# DEBUGSS_DRM register map
Vendor: Texas Instruments
Peripheral module from a debugger description file (folder am437x).
Registers are 32-bit, access per field, no defined reset value unless marked. A register's access mark holds for its fields unless they carry their own. Offsets are as the file gives them; lines under a group give offsets from that group; [hi:lo] are bit positions; {n}, {i} and the like mark numbered series; 'fields as' and 'values as' point back to an identical list; <NAME> marks a mode.

## DRM
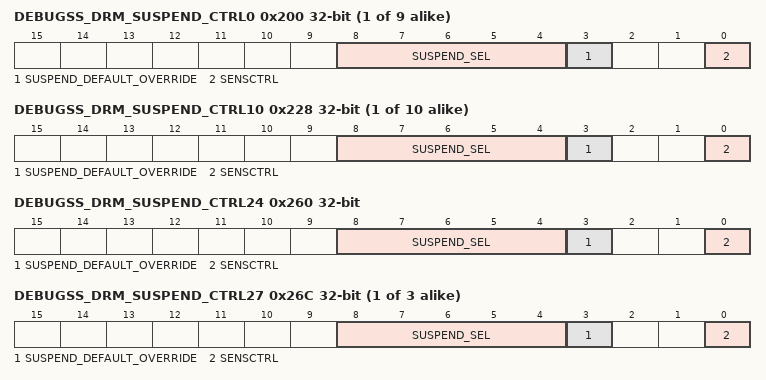
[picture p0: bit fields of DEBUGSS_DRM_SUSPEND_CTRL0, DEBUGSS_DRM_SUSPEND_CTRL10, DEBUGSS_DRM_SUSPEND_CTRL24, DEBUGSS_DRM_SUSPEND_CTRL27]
{0x200+4i} DEBUGSS_DRM_SUSPEND_CTRL{i} (i=0..8)
  [8:4] SUSPEND_SEL rw — Suspend signal selection. [[br]]Selects which suspend signal affects the peripheral. [[br]]Only valid when Suspend_Default_Override=0 and SensCtrl=1. [[br]]When read, these bits reflect the default suspend signal. [[br]]0000b: Cortex-A9 suspend signal. [[br]]All other values are reserved.
  [3] SUSPEND_DEFAULT_OVERRIDE ro — Enable or disable the override value in Suspend_Sel. [[br]]0: Suspend_Sel field will select which suspend signal reaches the peripheral. [[br]]1: Suspend_Sel field ignored. [[br]]Default suspend signal will reach the peripheral.
  [0] SENSCTRL rw — Sensitivity Control for suspend signals. [[br]]When Suspend_Default_Override=1, this bit is ignored and read as a 1. [[br]]When Suspend_Default_Override=0, [[br]]0: Suspend signal will not reach the peripheral. [[br]]Peripheral will act as normal even during a debug halt. [[br]]1: Suspend signal will reach the peripheral. [[br]]Peripheral will be suspended during debug halt.
{0x200+4i} DEBUGSS_DRM_SUSPEND_CTRL{i} (i=10..19)
  fields as DEBUGSS_DRM_SUSPEND_CTRL0
0x260 DEBUGSS_DRM_SUSPEND_CTRL24
  fields as DEBUGSS_DRM_SUSPEND_CTRL0
{0x200+4i} DEBUGSS_DRM_SUSPEND_CTRL{i} (i=27..29)
  fields as DEBUGSS_DRM_SUSPEND_CTRL0
